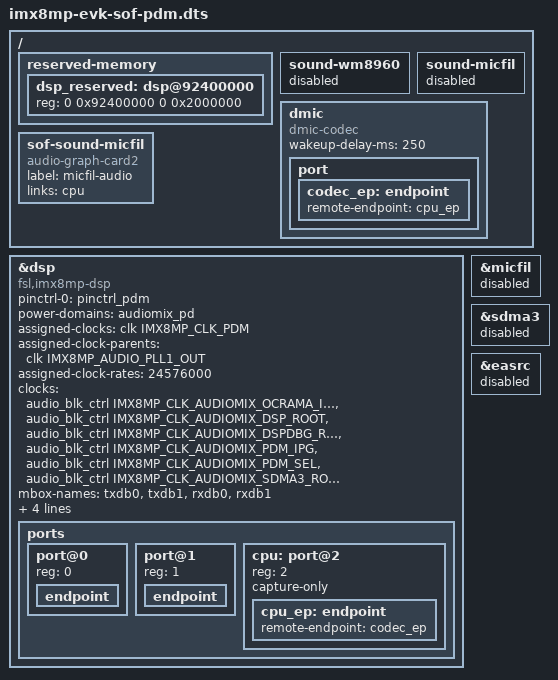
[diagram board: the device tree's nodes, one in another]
// SPDX-License-Identifier: GPL-2.0+
// Copyright NXP 2023

#include "imx8mp-evk.dts"

/delete-node/ &dsp_reserved_heap;
/delete-node/ &dsp_vdev0vring0;
/delete-node/ &dsp_vdev0vring1;
/delete-node/ &dsp_vdev0buffer;

/ {
	reserved-memory {
		dsp_reserved: dsp@92400000 {
			reg = <0 0x92400000 0 0x2000000>;
		};
	};

	sound-wm8960 {
		status = "disabled";
	};

	sound-micfil {
		status = "disabled";
	};

	dmic: dmic {
		#sound-dai-cells = <0>;
		compatible = "dmic-codec";
		wakeup-delay-ms = <250>;

		port { codec_ep: endpoint { remote-endpoint  = <&cpu_ep>; }; };
	};

	sof-sound-micfil {
		compatible = "audio-graph-card2";
		label = "micfil-audio";
		links = <&cpu>;

	};
};

&dsp {
	#sound-dai-cells = <1>;
	compatible = "fsl,imx8mp-dsp";

	pinctrl-names = "default";
	pinctrl-0 = <&pinctrl_pdm>;

	power-domains = <&audiomix_pd>;

	assigned-clocks = <&clk IMX8MP_CLK_PDM>;
	assigned-clock-parents = <&clk IMX8MP_AUDIO_PLL1_OUT>;
	assigned-clock-rates = <24576000>;

	clocks = <&audio_blk_ctrl IMX8MP_CLK_AUDIOMIX_OCRAMA_IPG>,
		<&audio_blk_ctrl IMX8MP_CLK_AUDIOMIX_DSP_ROOT>,
		<&audio_blk_ctrl IMX8MP_CLK_AUDIOMIX_DSPDBG_ROOT>,
		<&audio_blk_ctrl IMX8MP_CLK_AUDIOMIX_PDM_IPG>,
		<&audio_blk_ctrl IMX8MP_CLK_AUDIOMIX_PDM_SEL>,
		<&audio_blk_ctrl IMX8MP_CLK_AUDIOMIX_SDMA3_ROOT>;
	clock-names = "ipg", "ocram", "core", "pdm_ipg_clk", "pdm_ipg_clk_app", "sdma3_root";

	mbox-names = "txdb0", "txdb1", "rxdb0", "rxdb1";
	mboxes = <&mu2 2 0>, <&mu2 2 1>,
		 <&mu2 3 0>, <&mu2 3 1>;
	memory-region = <&dsp_reserved>;
	/delete-property/ firmware-name;

	tplg-name = "sof-imx8mp-wm8960.tplg";
	machine-drv-name = "asoc-audio-graph-card2";
	status = "okay";
	ports {
		#address-cells = <1>;
		#size-cells = <0>;

		port@0 { reg = <0>; endpoint { /* not used */ }; };
		port@1 { reg = <1>; endpoint { /* not used */ }; };
		cpu: port@2 {
			reg = <2>;
			capture-only;
			cpu_ep: endpoint { remote-endpoint = <&codec_ep>; };
		};
	};
};

&micfil {
	status = "disabled";
};

&sdma3 {
	status = "disabled";
};

&easrc {
	status = "disabled";
};
